AUTOSAR XML (schema 4-2-1)
package /MICROSAR/Dcm_swc
  mode declaration group DcmDiagnosticSessionControl: category=EXPLICIT_ORDER, initial-mode=DefaultSession, on-transition-value=255
    mode DefaultSession: value=1
    mode ProgrammingSession: value=2
    mode ExtendedSession: value=3
  mode declaration group DcmCommunicationControl: category=EXPLICIT_ORDER, initial-mode=DCM_ENABLE_RX_TX_NORM, on-transition-value=12
    12 x mode:
      DCM_ENABLE_RX_TX_NORM: value=0
      DCM_ENABLE_RX_DISABLE_TX_NORM: value=1
      DCM_DISABLE_RX_ENABLE_TX_NORM: value=2
      DCM_DISABLE_RX_TX_NORMAL: value=3
      DCM_ENABLE_RX_TX_NM: value=4
      DCM_ENABLE_RX_DISABLE_TX_NM: value=5
      DCM_DISABLE_RX_ENABLE_TX_NM: value=6
      DCM_DISABLE_RX_TX_NM: value=7
      DCM_ENABLE_RX_TX_NORM_NM: value=8
      DCM_ENABLE_RX_DISABLE_TX_NORM_NM: value=9
      DCM_DISABLE_RX_ENABLE_TX_NORM_NM: value=10
      DCM_DISABLE_RX_TX_NORM_NM: value=11
  data type mapping set DcmMappingSet  # Contains mapping for ModeDeclarationGroups which are provided by Dcm.
    mode-request-type-maps:
      implementation-data-type=Dcm_DiagnosticSessionControlType, mode-group=DcmDiagnosticSessionControl
      implementation-data-type=Dcm_CommunicationModeType, mode-group=DcmCommunicationControl
package /MICROSAR/Dcm_swc/DataTypes
  8 x impl type, all with category=TYPE_REFERENCE, implementation-data-type=uint8:
    Dcm_ConfirmationStatusType: compu {0=DCM_RES_POS_OK, 1=DCM_RES_POS_NOT_OK, 2=DCM_RES_NEG_OK, 3=DCM_RES_NEG_NOT_OK}
    Dcm_OpStatusType: compu {0=DCM_INITIAL, 1=DCM_PENDING, 2=DCM_CANCEL, 3=DCM_FORCE_RCRRP_OK, 64=DCM_FORCE_RCRRP_NOT_OK}
    Dcm_NegativeResponseCodeType: compu {0=DCM_E_POSITIVERESPONSE, 16=DCM_E_GENERALREJECT, 17=DCM_E_SERVICENOTSUPPORTED, 18=DCM_E_SUBFUNCTIONNOTSUPPORTED, 19=DCM_E_INCORRECTMESSAGELENGTHORINVALIDFORMAT, 20=DCM_E_RESPONSETOOLONG, 33=DCM_E_BUSYREPEATREQUEST, 34=DCM_E_CONDITIONSNOTCORRECT, 36=DCM_E_REQUESTSEQUENCEERROR, 37=DCM_E_NORESPONSEFROMSUBNETCOMPONENT, 38=DCM_E_FAILUREPREVENTSEXECUTIONOFREQUESTEDACTION, 49=DCM_E_REQUESTOUTOFRANGE, 51=DCM_E_SECURITYACCESSDENIED, 53=DCM_E_INVALIDKEY, 54=DCM_E_EXCEEDNUMBEROFATTEMPTS, 55=DCM_E_REQUIREDTIMEDELAYNOTEXPIRED, 112=DCM_E_UPLOADDOWNLOADNOTACCEPTED, 113=DCM_E_TRANSFERDATASUSPENDED, 114=DCM_E_GENERALPROGRAMMINGFAILURE, 115=DCM_E_WRONGBLOCKSEQUENCECOUNTER, 120=DCM_E_REQUESTCORRECTLYRECEIVEDRESPONSEPENDING, 126=DCM_E_SUBFUNCTIONNOTSUPPORTEDINACTIVESESSION, 127=DCM_E_SERVICENOTSUPPORTEDINACTIVESESSION, 129=DCM_E_RPMTOOHIGH, 130=DCM_E_RPMTOOLOW, 131=DCM_E_ENGINEISRUNNING, 132=DCM_E_ENGINEISNOTRUNNING, 133=DCM_E_ENGINERUNTIMETOOLOW, 134=DCM_E_TEMPERATURETOOHIGH, 135=DCM_E_TEMPERATURETOOLOW, 136=DCM_E_VEHICLESPEEDTOOHIGH, 137=DCM_E_VEHICLESPEEDTOOLOW, 138=DCM_E_THROTTLE_PEDALTOOHIGH, 139=DCM_E_THROTTLE_PEDALTOOLOW, 140=DCM_E_TRANSMISSIONRANGENOTINNEUTRAL, 141=DCM_E_TRANSMISSIONRANGENOTINGEAR, 143=DCM_E_BRAKESWITCH_NOTCLOSED, 144=DCM_E_SHIFTERLEVERNOTINPARK, 145=DCM_E_TORQUECONVERTERCLUTCHLOCKED, 146=DCM_E_VOLTAGETOOHIGH, 147=DCM_E_VOLTAGETOOLOW, 240..249=DCM_E_VMSCNC_0..DCM_E_VMSCNC_9, 250=DCM_E_VMSCNC_A, 251=DCM_E_VMSCNC_B, 252=DCM_E_VMSCNC_C, 253=DCM_E_VMSCNC_D, 254=DCM_E_VMSCNC_E}
    Dcm_ProtocolType: compu {0=DCM_OBD_ON_CAN, 1=DCM_OBD_ON_FLEXRAY, 2=DCM_OBD_ON_IP, 3=DCM_UDS_ON_CAN, 4=DCM_UDS_ON_FLEXRAY, 5=DCM_UDS_ON_IP, 12=DCM_NO_ACTIVE_PROTOCOL, 240..254=DCM_SUPPLIER_1..DCM_SUPPLIER_15}
    Dcm_RequestKindType: compu {0=DCM_REQ_KIND_NONE, 1=DCM_REQ_KIND_EXTERNAL, 2=DCM_REQ_KIND_ROE}
    Dcm_SesCtrlType: compu {1=DCM_DEFAULT_SESSION, 2=DCM_PROGRAMMING_SESSION, 3=DCM_EXTENDED_DIAGNOSTIC_SESSION}
    Dcm_DiagnosticSessionControlType: compu {1=DCM_ENUM_DefaultSession, 2=DCM_ENUM_ProgrammingSession, 3=DCM_ENUM_ExtendedSession}
    Dcm_CommunicationModeType: compu {0=DCM_ENABLE_RX_TX_NORM, 1=DCM_ENABLE_RX_DISABLE_TX_NORM, 2=DCM_DISABLE_RX_ENABLE_TX_NORM, 3=DCM_DISABLE_RX_TX_NORMAL, 4=DCM_ENABLE_RX_TX_NM, 5=DCM_ENABLE_RX_DISABLE_TX_NM, 6=DCM_DISABLE_RX_ENABLE_TX_NM, 7=DCM_DISABLE_RX_TX_NM, 8=DCM_ENABLE_RX_TX_NORM_NM, 9=DCM_ENABLE_RX_DISABLE_TX_NORM_NM, 10=DCM_DISABLE_RX_ENABLE_TX_NORM_NM, 11=DCM_DISABLE_RX_TX_NORM_NM}
package /MICROSAR/Dcm_swc/Interfaces
  mode switch interface DcmDiagnosticSessionControl: is-service=true, service-kind=DIAGNOSTIC-COMMUNICATION-MANAGER
    mode group DcmDiagnosticSessionControl: type=DcmDiagnosticSessionControl
  mode switch interface DcmCommunicationControl_ComMConf_ComMChannel_CAN00_f26020e5: is-service=true, service-kind=DIAGNOSTIC-COMMUNICATION-MANAGER
    mode group DcmCommunicationControl_ComMConf_ComMChannel_CAN00_f26020e5: type=DcmCommunicationControl
  client server interface DCMServices: is-service=true, service-kind=DIAGNOSTIC-COMMUNICATION-MANAGER
    5 x operation:
      GetActiveProtocol: possible-error=E_OK
        arg ActiveProtocol: type=Dcm_ProtocolType, direction=OUT
      GetSesCtrlType: possible-error=E_OK
        arg SesCtrlType: type=Dcm_SesCtrlType, direction=OUT
      ResetToDefaultSession: possible-error=E_OK
      SetActiveDiagnostic: possible-error=E_OK
        arg active: type=boolean, direction=IN
      GetRequestKind: possible-error=E_NOT_OK
        arg TesterSourceAddress: type=uint16, direction=IN
        arg RequestKind: type=Dcm_RequestKindType, direction=OUT
    error E_OK: error-code=0
    error E_NOT_OK: error-code=1
package /MICROSAR/Dcm_swc/ComponentTypes
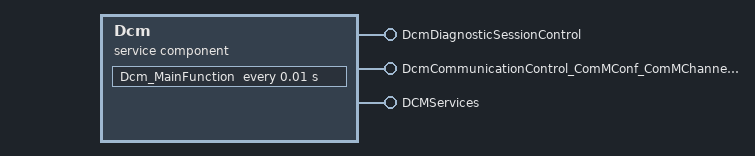
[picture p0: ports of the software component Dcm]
  service sw component type Dcm: category=SERVICE_COMPONENT
    provide port DcmDiagnosticSessionControl: provided-interface=DcmDiagnosticSessionControl
    provide port DcmCommunicationControl_ComMConf_ComMChannel_CAN00_f26020e5: provided-interface=DcmCommunicationControl_ComMConf_ComMChannel_CAN00_f26020e5
    provide port DCMServices: provided-interface=DCMServices
    behavior DcmInternalBehavior: data-type-mapping=DcmMappingSet, handle-termination-and-restart=NO-SUPPORT, included-data-type-set=data-type=[Dcm_ConfirmationStatusType, Dcm_OpStatusType, Dcm_NegativeResponseCodeType, Dcm_ProtocolType, Dcm_RequestKindType, Dcm_SesCtrlType, Dcm_DiagnosticSessionControlType, Dcm_CommunicationModeType]
      timing event Timer_Dcm_MainFunction: start-on-event=Dcm_MainFunction, period=0.01
      5 x operation invoked event:
        OpEventGetActiveProtocol_GetActiveProtocol_DCMServices: start-on-event=GetActiveProtocol, operation=DCMServices.GetActiveProtocol
        OpEventGetSesCtrlType_GetSesCtrlType_DCMServices: start-on-event=GetSesCtrlType, operation=DCMServices.GetSesCtrlType
        OpEventResetToDefaultSession_ResetToDefaultSession_DCMServices: start-on-event=ResetToDefaultSession, operation=DCMServices.ResetToDefaultSession
        OpEventSetActiveDiagnostic_SetActiveDiagnostic_DCMServices: start-on-event=SetActiveDiagnostic, operation=DCMServices.SetActiveDiagnostic
        OpEventGetRequestKind_GetRequestKind_DCMServices: start-on-event=GetRequestKind, operation=DCMServices.GetRequestKind
      port-api-options:
        enable-take-address=true, indirect-api=false, port=DcmDiagnosticSessionControl
        enable-take-address=true, indirect-api=false, port=DcmCommunicationControl_ComMConf_ComMChannel_CAN00_f26020e5
        enable-take-address=true, indirect-api=false, port=DCMServices
      6 x runnable:
        Dcm_MainFunction
          mode switch point ModeSwitchPointDcm_MainFunction_DcmDiagnosticSessionControl_DcmDiagnosticSessionControl: mode-group=DcmDiagnosticSessionControl.DcmDiagnosticSessionControl
          mode switch point ModeSwitchPointDcm_MainFunction_DcmCommunicationControl_ComMConf_ComMChannel_CAN00_f26020e5_DcmCommunicationControl_Com_ecad8657: mode-group=DcmCommunicationControl_ComMConf_ComMChannel_CAN00_f26020e5.DcmCommunicationControl_ComMConf_ComMChannel_CAN00_f26020e5
        GetActiveProtocol: can-be-invoked-concurrently=true, symbol=Dcm_GetActiveProtocol
        GetSesCtrlType: can-be-invoked-concurrently=true, symbol=Dcm_GetSesCtrlType
        ResetToDefaultSession: can-be-invoked-concurrently=true, symbol=Dcm_ResetToDefaultSession
        SetActiveDiagnostic: can-be-invoked-concurrently=true, symbol=Dcm_SetActiveDiagnostic
        GetRequestKind: can-be-invoked-concurrently=true, symbol=Dcm_GetRequestKind
  swc implementation DcmImplementation: programming-language=C, behavior=DcmInternalBehavior
